# CH579SFR register map
Vendor: WCH Ltd.; Series: CH57x; File version: 1.0
CPU: CM0 r0p0, little endian, no MPU, no FPU, 2 interrupt priority bits
Registers are 8-bit, read-write, reset 0x0 unless marked. A register's access mark holds for its fields unless they carry their own. Offsets are from the block's base; [hi:lo] are bit positions; {n}, {i} and the like mark numbered series.

## SYS — System Control Register
Base 0x40001000
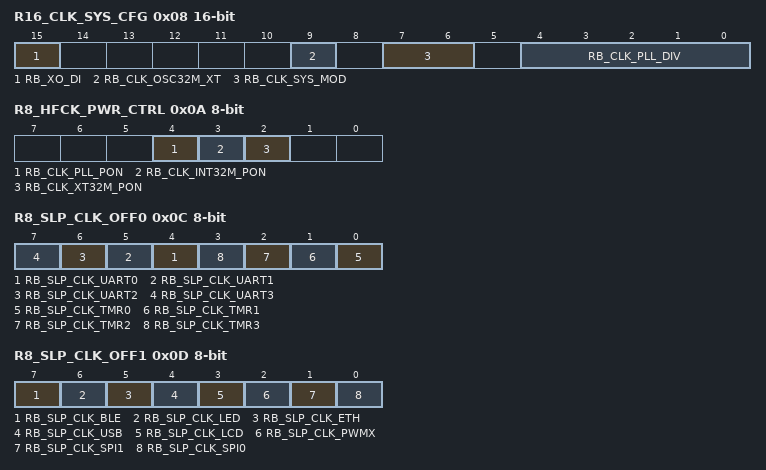
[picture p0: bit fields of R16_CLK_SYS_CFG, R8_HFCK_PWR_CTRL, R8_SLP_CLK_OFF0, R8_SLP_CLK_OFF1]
0x08 R16_CLK_SYS_CFG 16-bit access per field — RWA, system clock configuration, SAM
  [15] RB_XO_DI ro — RO, X32MO input status sample value
  [9] RB_CLK_OSC32M_XT rw — RWA, 32MHz clock source selection: 0=internal 32MHz oscillator, 1=external 32MHz oscillator
  [7:6] RB_CLK_SYS_MOD rw — RWA, system clock source mode: 00=divided from 32MHz, 01=divided from PLL-480MHz, 10=directly from 32MHz, 11=directly from 32KHz
  [4:0] RB_CLK_PLL_DIV rw — RWA, output clock divider from PLL or CK32M
0x0A R8_HFCK_PWR_CTRL — RWA, high frequency clock module power control, SAM
  [4] RB_CLK_PLL_PON — RWA, PLL power control: 0=power down, 1-power on
  [3] RB_CLK_INT32M_PON — RWA, internal 32MHz oscillator power control: 0=power down, 1-power on
  [2] RB_CLK_XT32M_PON — RWA, external 32MHz oscillator power control: 0=power down, 1-power on
0x0C R8_SLP_CLK_OFF0 — RWA, sleep clock off control byte 0, SAM
  [n+4] RB_SLP_CLK_UART{n} (n=0..3) — RWA, close UART{n} clock
  [n] RB_SLP_CLK_TMR{n} (n=0..3) — RWA, close TMR{n} clock
0x0D R8_SLP_CLK_OFF1 — RWA, sleep clock off control byte 1, SAM
  [7] RB_SLP_CLK_BLE — RWA, close BLE clock
  [6] RB_SLP_CLK_LED — RWA, close LED clock
  [5] RB_SLP_CLK_ETH — RWA, close ETH clock
  [4] RB_SLP_CLK_USB — RWA, close USB clock
  [3] RB_SLP_CLK_LCD — RWA, close LCD clock
  [2] RB_SLP_CLK_PWMX — RWA, close PWMx clock
  [1] RB_SLP_CLK_SPI1 — RWA, close SPI1 clock
  [0] RB_SLP_CLK_SPI0 — RWA, close SPI0 clock
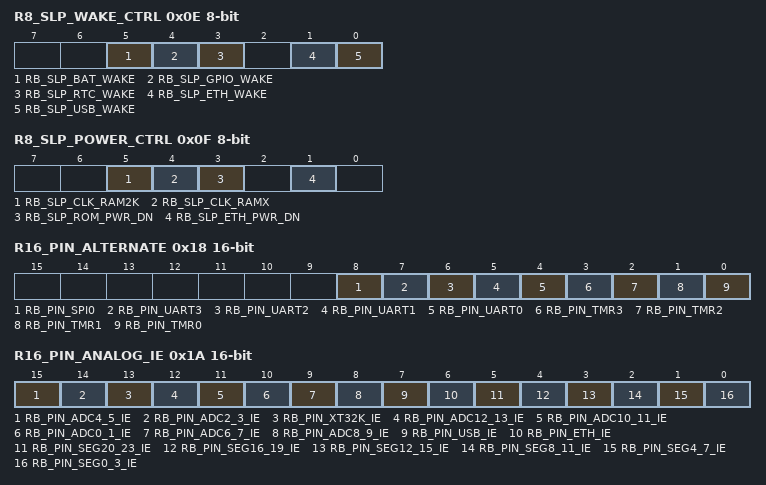
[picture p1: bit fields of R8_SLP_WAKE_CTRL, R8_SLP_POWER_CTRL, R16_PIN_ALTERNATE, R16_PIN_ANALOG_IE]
0x0E R8_SLP_WAKE_CTRL — RWA, wake control, SAM
  [5] RB_SLP_BAT_WAKE — RWA, enable BAT waking
  [4] RB_SLP_GPIO_WAKE — RWA, enable GPIO waking
  [3] RB_SLP_RTC_WAKE — RWA, enable RTC waking
  [1] RB_SLP_ETH_WAKE — RWA, enable ETH waking
  [0] RB_SLP_USB_WAKE — RWA, enable USB waking
0x0F R8_SLP_POWER_CTRL — RWA, peripherals power down control, SAM
  [5] RB_SLP_CLK_RAM2K — RWA, close retention 2KB SRAM clock
  [4] RB_SLP_CLK_RAMX — RWA, close main SRAM clock
  [3] RB_SLP_ROM_PWR_DN — RWA, enable Flash ROM power down during halt
  [1] RB_SLP_ETH_PWR_DN — RWA, enable ETH PHY power down
0x18 R16_PIN_ALTERNATE 16-bit — RW, function pin alternate configuration
  [8] RB_PIN_SPI0 — RW, SCS/SCK0/MOSI/MISO alternate pin enable: 0=SCS/SCK0/MOSI/MISO on PA[12]/PA[13]/PA[14]/PA[15], 1=SCS_/SCK0_/MOSI_/MISO_ on PB[12]/PB[13]/PB[14]/PB[15]
  [7] RB_PIN_UART3 — RW, RXD3/TXD3 alternate pin enable: 0=RXD3/TXD3 on PA[4]/PA[5], 1=RXD3_/TXD3_ on PB[20]/PB[21]
  [6] RB_PIN_UART2 — RW, RXD2/TXD2 alternate pin enable: 0=RXD2/TXD2 on PA[6]/PA[7], 1=RXD2_/TXD2_ on PB[22]/PB[23]
  [5] RB_PIN_UART1 — RW, RXD1/TXD1 alternate pin enable: 0=RXD1/TXD1 on PA[8]/PA[9], 1=RXD1_/TXD1_ on PB[8]/PB[9]
  [4] RB_PIN_UART0 — RW, RXD0/TXD0 alternate pin enable: 0=RXD0/TXD0 on PB[4]/PB[7], 1=RXD0_/TXD0_ on PA[15]/PA[14]
  [3] RB_PIN_TMR3 — RW, TMR3 alternate pin enable: 0=TMR3/PWM3/CAP3 on PA[2], 1=TMR3_/PWM3_/CAP3_ on PB[18]
  [2] RB_PIN_TMR2 — RW, TMR2 alternate pin enable: 0=TMR2/PWM2/CAP2 on PA[11], 1=TMR2_/PWM2_/CAP2_ on PB[11]
  [1] RB_PIN_TMR1 — RW, TMR1 alternate pin enable: 0=TMR1/PWM1/CAP1 on PA[10], 1=TMR1_/PWM1_/CAP1_ on PB[10]
  [0] RB_PIN_TMR0 — RW, TMR0 alternate pin enable: 0=TMR0/PWM0/CAP0 on PA[3], 1=TMR0_/PWM0_/CAP0_ on PB[19]
0x1A R16_PIN_ANALOG_IE 16-bit — RW, analog pin enable and digital input disable
  [15] RB_PIN_ADC4_5_IE — RW, ADC/TouchKey channel 4/5 digital input disable: 0=digital input enable, 1=digital input disable
  [14] RB_PIN_ADC2_3_IE — RW, ADC/TouchKey channel 2/3 digital input disable: 0=digital input enable, 1=digital input disable
  [13] RB_PIN_XT32K_IE — RW, external 32KHz oscillator digital input disable: 0=digital input enable, 1=digital input disable
  [12] RB_PIN_ADC12_13_IE — RW, ADC/TouchKey channel 12/13 digital input disable: 0=digital input enable, 1=digital input disable
  [11] RB_PIN_ADC10_11_IE — RW, ADC/TouchKey channel 10/11 digital input disable: 0=digital input enable, 1=digital input disable
  [10] RB_PIN_ADC0_1_IE — RW, ADC/TouchKey channel 0/1 digital input disable: 0=digital input enable, 1=digital input disable
  [9] RB_PIN_ADC6_7_IE — RW, ADC/TouchKey channel 7/6 digital input disable: 0=digital input enable, 1=digital input disable
  [8] RB_PIN_ADC8_9_IE — RW, ADC/TouchKey channel 9/8 digital input disable: 0=digital input enable, 1=digital input disable
  [7] RB_PIN_USB_IE — RW, USB analog I/O enable: 0=analog I/O disable, 1=analog I/O enable
  [6] RB_PIN_ETH_IE — RW, ETH analog I/O enable and digital input disable: 0=analog I/O disable and digital input enable, 1=analog I/O enable and digital input disable
  [5] RB_PIN_SEG20_23_IE — RW, LCD segment 20~23 digital input disable: 0=digital input enable, 1=digital input disable
  [4] RB_PIN_SEG16_19_IE — RW, LCD segment 16~19 digital input disable: 0=digital input enable, 1=digital input disable
  [3] RB_PIN_SEG12_15_IE — RW, LCD segment 12~15 digital input disable: 0=digital input enable, 1=digital input disable
  [2] RB_PIN_SEG8_11_IE — RW, LCD segment 8~11 digital input disable: 0=digital input enable, 1=digital input disable
  [1] RB_PIN_SEG4_7_IE — RW, LCD segment 4~7 digital input disable: 0=digital input enable, 1=digital input disable
  [0] RB_PIN_SEG0_3_IE — RW, LCD segment 0~3 digital input disable: 0=digital input enable, 1=digital input disable
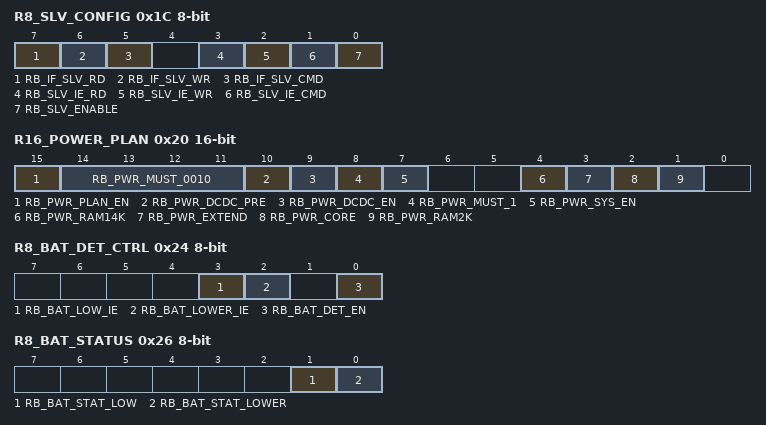
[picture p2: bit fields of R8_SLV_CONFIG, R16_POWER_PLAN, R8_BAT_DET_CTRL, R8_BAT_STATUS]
0x1C R8_SLV_CONFIG — RW, parallel slave configuration
  [7] RB_IF_SLV_RD — RW1, interrupt flag of parallel slave reading event
  [6] RB_IF_SLV_WR — RW1, interrupt flag of parallel slave writing event
  [5] RB_IF_SLV_CMD ro — RO, parallel slave command synchronous flag
  [3] RB_SLV_IE_RD — RW, enable interrupt for slave reading event
  [2] RB_SLV_IE_WR — RW, enable interrupt for slave writing event
  [1] RB_SLV_IE_CMD — RW, enable interrupt for slave writing command event
  [0] RB_SLV_ENABLE — RW, parallel slave enable
0x20 R16_POWER_PLAN 16-bit — RWA, power plan before sleep instruction, SAM
  [15] RB_PWR_PLAN_EN — RWA/WZ, power plan enable, auto clear after sleep executed
  [14:11] RB_PWR_MUST_0010 ro — RWA, must write 0010
  [10] RB_PWR_DCDC_PRE — RWA, DC/DC converter pre-enable
  [9] RB_PWR_DCDC_EN — RWA, DC/DC converter enable: 0=DC/DC disable and bypass, 1=DC/DC enable
  [8] RB_PWR_MUST_1 ro — RWA, must write 1
  [7] RB_PWR_SYS_EN — RWA, power for system
  [4] RB_PWR_RAM14K — RWA, power for main SRAM
  [3] RB_PWR_EXTEND — RWA, power retention for USB and BLE
  [2] RB_PWR_CORE — RWA, power retention for core and base peripherals
  [1] RB_PWR_RAM2K — RWA, power for retention 2KB SRAM
0x22 R8_AUX_POWER_ADJ access per field — RWA, aux power adjust control, SAM
  [2:0] RB_ULPLDO_ADJ rw — RWA, Ultra-Low-Power LDO voltage adjust
0x24 R8_BAT_DET_CTRL — RWA, battery voltage detector control, SAM
  [3] RB_BAT_LOW_IE — RWA, interrupt enable for battery low voltage
  [2] RB_BAT_LOWER_IE — RWA, interrupt enable for battery lower voltage
  [0] RB_BAT_DET_EN — RWA, battery voltage detector enable
0x25 R8_BAT_DET_CFG — RWA, battery voltage detector configuration, SAM
  [1:0] RB_BAT_LOW_VTH — RWA, select threshold voltage of battery voltage low
0x26 R8_BAT_STATUS ro — RO, battery status
  [1] RB_BAT_STAT_LOW — RO, battery low voltage status, high action
  [0] RB_BAT_STAT_LOWER — RO, battery lower voltage status, high action
0x2C R16_INT32K_TUNE 16-bit — RWA, internal 32KHz oscillator tune control, SAM
  [9:0] RB_INT32K_TUNE — RWA, internal 32KHz oscillator frequency tune
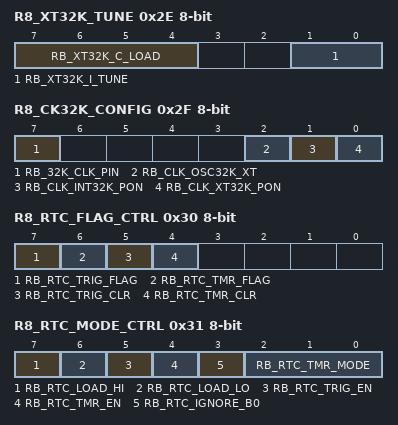
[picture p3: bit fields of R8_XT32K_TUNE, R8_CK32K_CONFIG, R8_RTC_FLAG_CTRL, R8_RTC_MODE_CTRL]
0x2E R8_XT32K_TUNE — RWA, external 32KHz oscillator tune control, SAM
  [7:4] RB_XT32K_C_LOAD — RWA, external 32KHz oscillator load capacitor tune: Cap = RB_XT32K_C_LOAD + 12pF
  [1:0] RB_XT32K_I_TUNE — RWA, external 32KHz oscillator current tune: 00=75% current, 01=standard current, 10=150% current, 11=200% current
0x2F R8_CK32K_CONFIG access per field — RWA, 32KHz oscillator configure
  [7] RB_32K_CLK_PIN ro — RO, 32KHz oscillator clock pin status
  [2] RB_CLK_OSC32K_XT rw — RWA, 32KHz oscillator source selection: 0=RC, 1=XT
  [1] RB_CLK_INT32K_PON rw — RWA, internal 32KHz oscillator power on
  [0] RB_CLK_XT32K_PON rw — RWA, external 32KHz oscillator power on
0x30 R8_RTC_FLAG_CTRL access per field — RW, RTC flag and clear control
  [7] RB_RTC_TRIG_FLAG ro — RO, RTC trigger action flag
  [6] RB_RTC_TMR_FLAG ro — RO, RTC timer action flag
  [5] RB_RTC_TRIG_CLR rw — RW, set 1 to clear RTC trigger action flag, auto clear
  [4] RB_RTC_TMR_CLR rw — RW, set 1 to clear RTC timer action flag, auto clear
0x31 R8_RTC_MODE_CTRL — RWA, RTC mode control, SAM
  [7] RB_RTC_LOAD_HI — RWA, set 1 to load RTC count high word R32_RTC_CNT_DAY, auto clear after loaded
  [6] RB_RTC_LOAD_LO — RWA, set 1 to load RTC count low word R32_RTC_CNT_32K, auto clear after loaded
  [5] RB_RTC_TRIG_EN — RWA, RTC trigger mode enable
  [4] RB_RTC_TMR_EN — RWA, RTC timer mode enable
  [3] RB_RTC_IGNORE_B0 — RWA, force ignore bit0 for trigger mode: 0=compare bit0, 1=ignore bit0
  [2:0] RB_RTC_TMR_MODE — RWA, RTC timer mode: 000=0.125S, 001=0.25S, 010=0.5S, 011=1S, 100=2S, 101=4S, 110=8S, 111=16S
0x34 R32_RTC_TRIG 32-bit — RWA, RTC trigger value, SAM
0x38 R16_RTC_CNT_32K 16-bit ro — RO, RTC count based 32KHz
0x3A R16_RTC_CNT_2S 16-bit ro — RO, RTC count based 2 second
0x3C R32_RTC_CNT_DAY 32-bit ro — RO, RTC count based one day, only low 14 bit
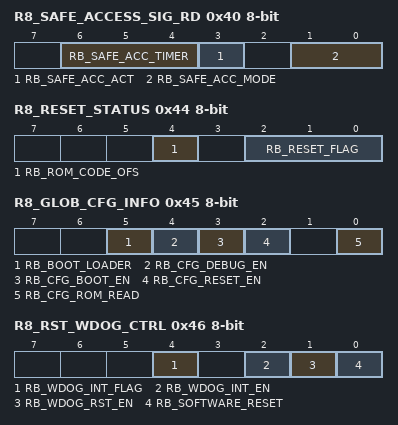
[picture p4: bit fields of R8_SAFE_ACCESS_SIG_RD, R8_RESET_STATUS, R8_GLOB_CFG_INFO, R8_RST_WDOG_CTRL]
0x40 R8_SAFE_ACCESS_SIG_RD ro — R8_SAFE_ACCESS_SIG_RD Register safe accessing
  [6:4] RB_SAFE_ACC_TIMER — RO, safe accessing timer bit mask (16*clock number)
  [3] RB_SAFE_ACC_ACT — RO, indicate safe accessing status now: 0=locked, read only, 1=safe/unlocked (SAM), write enabled
  [1:0] RB_SAFE_ACC_MODE — RO, current safe accessing mode: 11=safe/unlocked (SAM), other=locked (00..01..10..11)
0x40 R8_SAFE_ACCESS_SIG_WR wo — safe accessing sign register, must write 0x57 then 0xA8 to enter safe accessing mode
0x41 R8_CHIP_ID ro — RF, chip ID register, always is ID_CH57*
0x42 R8_SAFE_ACCESS_ID ro — RF, safe accessing ID register, always 0x04
0x43 R8_WDOG_COUNT — RW, watch-dog count, count by clock frequency Fsys/131072
0x44 R8_RESET_STATUS access per field — RWA, reset status, SAM
  [4] RB_ROM_CODE_OFS rw — RWA, code offset address selection in Flash ROM: 0=start address 0x000000, 1=start address 0x008000
  [2:0] RB_RESET_FLAG ro — RO, recent reset flag
0x45 R8_GLOB_CFG_INFO ro — RO, global configuration information and status
  [5] RB_BOOT_LOADER — RO, indicate boot loader status: 0=application status (by software reset), 1=boot loader status
  [4] RB_CFG_DEBUG_EN — RO, debug enable status
  [3] RB_CFG_BOOT_EN — RO, boot-loader enable status
  [2] RB_CFG_RESET_EN — RO, manual reset input enable status
  [0] RB_CFG_ROM_READ — RO, indicate protected status of Flash ROM code and data: 0=reading protect, 1=enable read by external programmer
0x46 R8_RST_WDOG_CTRL — RWA, reset and watch-dog control, SAM
  [4] RB_WDOG_INT_FLAG — RW1, watch-dog timer overflow interrupt flag, cleared by RW1 or reload watch-dog count or __SEV(Send-Event)
  [2] RB_WDOG_INT_EN — RWA, watch-dog timer overflow interrupt enable: 0=disable, 1=enable
  [1] RB_WDOG_RST_EN — RWA, enable watch-dog reset if watch-dog timer overflow: 0=as timer only, 1=enable reset if timer overflow
  [0] RB_SOFTWARE_RESET wo — WA/WZ, global software reset, high action, auto clear
0x47 R8_GLOB_RESET_KEEP — RW, value keeper during global reset
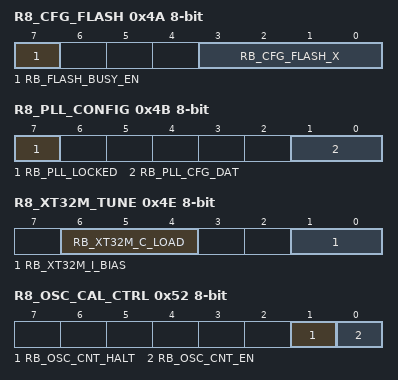
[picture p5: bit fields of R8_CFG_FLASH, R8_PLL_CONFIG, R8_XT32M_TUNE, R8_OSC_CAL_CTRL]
0x4A R8_CFG_FLASH — RWA, Flash ROM configure register
  [7] RB_FLASH_BUSY_EN — RWA, enable ROM busy if burst reading: 1-enable(suggest), 0-disable
  [3:0] RB_CFG_FLASH_X — RWA, Flash ROM configure data, keep the value unchanged if write
0x4B R8_PLL_CONFIG access per field — RWA, PLL configuration control, SAM
  [7] RB_PLL_LOCKED ro — RO, indicate PLL locked
  [1:0] RB_PLL_CFG_DAT rw — RWA, PLL configure data
0x4C R16_INT32M_CALIB 16-bit — RWA, internal 32MHz oscillator tune control, SAM
0x4E R8_XT32M_TUNE — RWA, external 32MHz oscillator tune control, SAM
  [6:4] RB_XT32M_C_LOAD — RWA, external 32MHz oscillator load capacitor tune: Cap = RB_XT32M_C_LOAD * 2 + 10pF
  [1:0] RB_XT32M_I_BIAS — RWA, external 32MHz oscillator bias current tune: 00=75% current, 01=standard current, 10=125% current, 11=150% current
0x50 R16_OSC_CAL_CNT 16-bit ro — RO, system clock count value for 32KHz 5 cycles
  [11:0] RB_OSC_CAL_CNT
0x52 R8_OSC_CAL_CTRL access per field — RWA, oscillator frequency calibration control, SAM
  [1] RB_OSC_CNT_HALT ro — RO, calibration counter halt status: 0=counting, 1=halt for reading count value
  [0] RB_OSC_CNT_EN rw — RWA, calibration counter enable
0x58 R8_ADC_CHANNEL — RW, ADC input channel selection
  [3:0] RB_ADC_CH_INX — RW, ADC input channel index
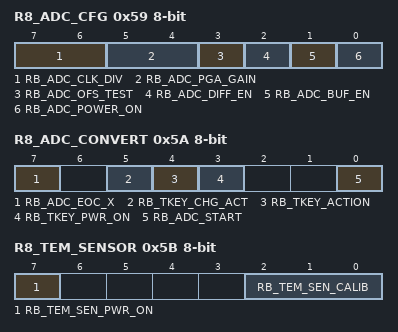
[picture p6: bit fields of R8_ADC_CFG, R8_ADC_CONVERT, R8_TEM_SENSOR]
0x59 R8_ADC_CFG — RW, ADC configure
  [7:6] RB_ADC_CLK_DIV — RW, select ADC clock frequency: 00=3.2MHz, 01=2.67MHz, 10=5.33MHz, 11=4MHz
  [5:4] RB_ADC_PGA_GAIN — RW, set ADC input PGA gain: 00=-12dB, 01=-6dB, 10=0dB, 11=6dB
  [3] RB_ADC_OFS_TEST — RW, enable ADC offset test mode: 0=normal mode, 1=short port4 to test offset
  [2] RB_ADC_DIFF_EN — RW, ADC input channel mode: 0=single-end, 1=differnetial
  [1] RB_ADC_BUF_EN — RW, ADC input buffer enable
  [0] RB_ADC_POWER_ON — RW, ADC power control: 0=power down, 1=power on
0x5A R8_ADC_CONVERT access per field — RW, ADC convert control
  [7] RB_ADC_EOC_X ro — RO, end of ADC conversion flag
  [5] RB_TKEY_CHG_ACT ro — RO, Touchkey capacity charge status: 0=free, 1=charge
  [4] RB_TKEY_ACTION ro — RO, Touchkey action status: 0=free, 1=discharge or charge or ADC
  [3] RB_TKEY_PWR_ON rw — RW, Touchkey power on: 0=power down, 1=power on
  [0] RB_ADC_START rw — RW, ADC convert start control: 0=stop ADC convert, 1=start an ADC convert, auto clear
0x5B R8_TEM_SENSOR — RW, temperature sensor control
  [7] RB_TEM_SEN_PWR_ON — RW, temperature sensor power control: 0=power down, 1=power on
  [2:0] RB_TEM_SEN_CALIB — RW, temperature sensor calibration
0x5C R16_ADC_DATA 16-bit ro — RO, ADC data
  [11:0] RB_ADC_DATA — RO, ADC conversion data
0x5E R8_ADC_INT_FLAG ro — RO, ADC interrupt flag register
  [7] RB_ADC_IF_EOC — RO, ADC conversion interrupt flag: 0=free or converting, 1=end of conversion, interrupt action, write R8_ADC_CONVERT to clear flag
0x5F R8_TKEY_CNT wo — WO, Touch-key charge and discharge count
0x90 R16_PA_INT_EN 16-bit — RW, GPIO PA interrupt enable
0x92 R16_PB_INT_EN 16-bit — RW, GPIO PB interrupt enable
0x94 R16_PA_INT_MODE 16-bit — RW, GPIO PA interrupt mode: 0=level action, 1=edge action
0x96 R16_PB_INT_MODE__R8_SLV_RD_STAT 16-bit — RW, GPIO PB interrupt mode: 0=level action, 1=edge action;RW, status for parallel slave read
0x97 R8_SLV_WR_DATA — RW, data or command from parallel slave write
0x9C R16_PA_INT_IF 16-bit — RW1, GPIO PA interrupt flag
0x9E R16_PB_INT_IF 16-bit — RW1, GPIO PB interrupt flag
0xA0 R32_PA_DIR 32-bit — RW, GPIO PA I/O direction: 0=in, 1=out
0xA4 R32_PA_PIN 32-bit ro — RO, GPIO PA input
0xA8 R32_PA_OUT 32-bit — RW, GPIO PA output
0xAC R32_PA_CLR 32-bit — WZ, GPIO PA clear output: 0=keep, 1=clear
0xB0 R32_PA_PU 32-bit — RW, GPIO PA pullup resistance enable
0xB4 R32_PA_PD_DRV 32-bit — RW, PA pulldown for input or PA driving capability for output
0xC0 R32_PB_DIR 32-bit — RW, GPIO PB I/O direction: 0=in, 1=out
0xC4 R32_PB_PIN 32-bit ro — RO, GPIO PB input
0xC8 R32_PB_OUT__R8_SLV_RD_DATA 32-bit — RW, GPIO PB output;RW, data for parallel slave read
0xCC R32_PB_CLR 32-bit — WZ, GPIO PB clear output: 0=keep, 1=clear
0xD0 R32_PB_PU 32-bit — RW, GPIO PB pullup resistance enable
0xD4 R32_PB_PD_DRV 32-bit — RW, PB pulldown for input or PB driving capability for output
